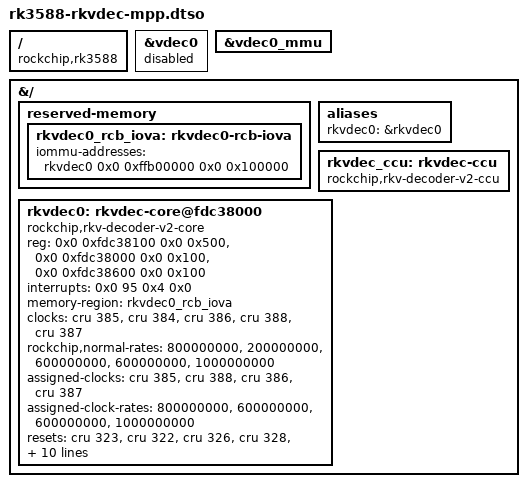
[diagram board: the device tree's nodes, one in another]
// SPDX-License-Identifier: (GPL-2.0+ OR MIT)
/*
 * DTS overlay: replace mainline vdec0 with MPP decoder binding.
 *
 * The VDPU381 hardware lives at vdec0 (0xfdc38000) with the mainline
 * stateless rkvdec driver.  This overlay disables that binding and
 * replaces it with a stateful MPP decoder node so our rkvdec2 driver
 * (which speaks /dev/mpp_service) can claim the hardware.
 *
 * Numeric IDs:
 *   Clocks:  ACLK_RKVDEC0=385  HCLK_RKVDEC0=384  CLK_RKVDEC0_CA=386
 *            CLK_RKVDEC0_CORE=388  CLK_RKVDEC0_HEVC_CA=387
 *   Resets:  SRST_A_RKVDEC0=323  SRST_H_RKVDEC0=322
 *            SRST_RKVDEC0_CA=326  SRST_RKVDEC0_CORE=328
 *            SRST_RKVDEC0_HEVC_CA=327
 *   Power:   RK3588_PD_RKVDEC0=14
 *   IRQ:     GIC_SPI 95 (core), 96 (mmu)
 */

/dts-v1/;
/plugin/;

/ {
	compatible = "rockchip,rk3588";
};

/* Disable the mainline stateless rkvdec DRIVER, but keep its IOMMU
 * (vdec0_mmu) enabled — our rkvdec2 device reuses it for DMA.  The MMU
 * is a standalone platform device and probes regardless of whether its
 * master (vdec0) is enabled. */
&vdec0   { status = "disabled"; };
&vdec0_mmu { status = "okay"; };

&{/} {
	#address-cells = <2>;
	#size-cells = <2>;

	reserved-memory {
		#address-cells = <2>;
		#size-cells = <2>;
		ranges;

		rkvdec0_rcb_iova: rkvdec0-rcb-iova {
			iommu-addresses = <&rkvdec0 0x0 0xffb00000 0x0 0x100000>;
		};
	};

	aliases { rkvdec0 = &rkvdec0; };

	rkvdec_ccu: rkvdec-ccu {
		compatible = "rockchip,rkv-decoder-v2-ccu";
	};

	/* Decoder core — VDPU381 @ 0xfdc38000 */
	rkvdec0: rkvdec-core@fdc38000 {
		compatible = "rockchip,rkv-decoder-v2-core";
		reg = <0x0 0xfdc38100 0x0 0x500>,
		      <0x0 0xfdc38000 0x0 0x100>,
		      <0x0 0xfdc38600 0x0 0x100>;
		reg-names = "function", "link", "cache";
		interrupts = <0x0 95 0x4 0x0>;
		interrupt-names = "vdpu";
		memory-region = <&rkvdec0_rcb_iova>;
		clocks = <&cru 385>, <&cru 384>, <&cru 386>,
			 <&cru 388>, <&cru 387>;
		clock-names = "axi", "ahb", "cabac", "core", "hevc_cabac";
		rockchip,normal-rates = <800000000>, <200000000>, <600000000>,
					<600000000>, <1000000000>;
		assigned-clocks = <&cru 385>, <&cru 388>,
				  <&cru 386>, <&cru 387>;
		assigned-clock-rates = <800000000>, <600000000>,
				       <600000000>, <1000000000>;
		resets = <&cru 323>, <&cru 322>, <&cru 326>,
			 <&cru 328>, <&cru 327>;
		reset-names = "axi", "ahb", "cabac", "core", "hevc_cabac";
		rockchip,sram = <&vdec0_sram>;
		rockchip,rcb-iova = <0xffb00000 0x100000>;
		iommus = <&vdec0_mmu>;
		rockchip,srv = <&mpp_srv>;
		rockchip,ccu = <&rkvdec_ccu>;
		rockchip,taskqueue-node = <0>;
		rockchip,resetgroup-node = <0>;
		rockchip,task-capacity = <4>;
		power-domains = <&power 14>;
	};
};
